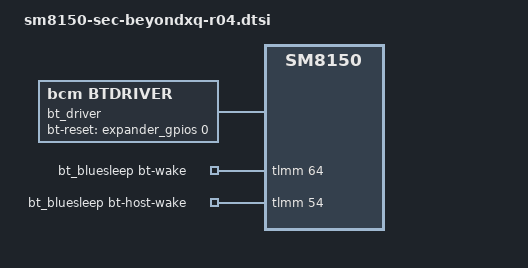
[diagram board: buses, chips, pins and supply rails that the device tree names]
/* Copyright (c) 2016-2017, The Linux Foundation. All rights reserved.
 *
 * This program is free software; you can redistribute it and/or modify
 * it under the terms of the GNU General Public License version 2 and
 * only version 2 as published by the Free Software Foundation.
 *
 * This program is distributed in the hope that it will be useful,
 * but WITHOUT ANY WARRANTY; without even the implied warranty of
 * MERCHANTABILITY or FITNESS FOR A PARTICULAR PURPOSE.  See the
 * GNU General Public License for more details.
 */

#include "sm8150-sec-beyondxq-common.dtsi"
#include "sm8150-sec-beyondxq-optics-r00.dtsi"

&soc {
	bt_driver {
		compatible = "bcm,btdriver";  //bt_en
		pinctrl-names = "default";
		bcm,bt-reset-gpio = <&expander_gpios 0 GPIO_ACTIVE_HIGH>;
		status = "okay";
	};

	bt_bluesleep {
		compatible = "bcm,bluesleep";
		bcm,bt-wake-gpio = <&tlmm 64 0>;
		bcm,bt-host-wake-gpio = <&tlmm 54 0>;
		pinctrl-names = "default";
		pinctrl-0 = <&bt_wake_default &bt_hostwake_default>;
		status = "okay";
	};
};

&cs35l41_r {
   reset-gpios = <&expander_gpios 11 0>;
   pinctrl-0 = <&cs35l41_int_active>;
};

